# PIC32CX1025MTSH128 device description
Architecture: CORTEX-M4; Family: PIC32CXMT; Series: PIC32CXMTSH
Registers are 32-bit, read-write, no defined reset value unless marked. A register's access mark holds for its fields unless they carry their own. Offsets are from the block's base; [hi:lo] are bit positions; {n}, {i} and the like mark numbered series.

## CMCC — Cortex-M Cache Controller
Instances: CMCC0 0x46008000, CMCC1 0x4600C000
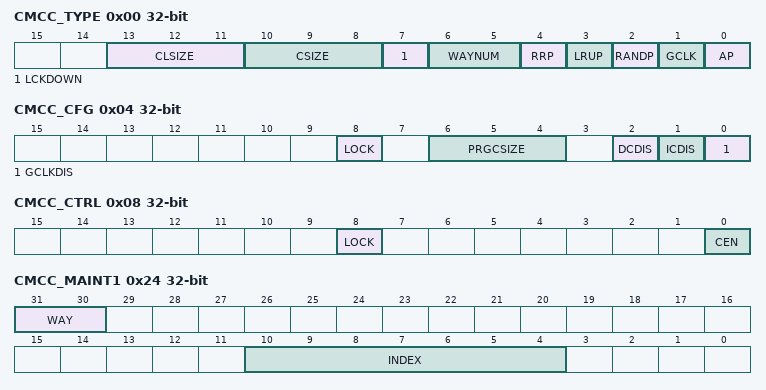
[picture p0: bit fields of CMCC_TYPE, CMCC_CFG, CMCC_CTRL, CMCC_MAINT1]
0x00 CMCC_TYPE ro — Cache Controller Type Register
  [13:11] CLSIZE — Cache LIne Size
    0=CLSIZE_1KB (Cache line size is 4 bytes); 1=CLSIZE_2KB (Cache line size is 8 bytes); 2=CLSIZE_4KB (Cache line size is 16 bytes); 3=CLSIZE_8KB (Cache line size is 32 bytes)
  [10:8] CSIZE — Data Cache Size
    0=CSIZE_1KB (Cache size is 1 Kbyte); 1=CSIZE_2KB (Cache size is 2 Kbytes); 2=CSIZE_4KB (Cache size is 4 Kbytes); 3=CSIZE_8KB (Cache size is 8 Kbytes); 4=CSIZE_16KB (Cache size is 16 Kbytes); 5=CSIZE_32KB (Cache size is 32 Kbytes); 6=CSIZE_64KB (Cache size is 64 Kbytes)
  [7] LCKDOWN — Lockdown Supported
  [6:5] WAYNUM — Number of Ways
    0=DMAPPED (Direct Mapped Cache); 1=ARCH2WAY (2-way set associative); 2=ARCH4WAY (4-way set associative); 3=ARCH8WAY (8-way set associative)
  [4] RRP — Random Selection Policy Supported
  [3] LRUP — Least Recently Used Policy Supported
  [2] RANDP — Random Selection Policy Supported
  [1] GCLK — Dynamic Clock Gating Supported
  [0] AP — Access Port Access Allowed
0x04 CMCC_CFG — Configuration Register
  [8] LOCK — Configuration Lock Until Next System Reset (Write-once)
  [6:4] PRGCSIZE — Programmable Cache Size
  [2] DCDIS — Data Caching Disable
  [1] ICDIS — Instruction Caching Disable
  [0] GCLKDIS — Disable Clock Gating
0x08 CMCC_CTRL wo — Control Register
  [8] LOCK — Control Lock Until Next System Reset (Write-once)
  [0] CEN — Cache Controller Enable
0x0C CMCC_SR ro — Status Register
  [0] CSTS — Cache Controller Status
0x20 CMCC_MAINT0 wo — Maintenance Register 0
  [0] INVALL — Cache Controller Invalidate All
0x24 CMCC_MAINT1 wo — Maintenance Register 1
  [31:30] WAY — Invalidate Way
    {v}=Way {v} is selection for index invalidation (v=0..3)
  [10:4] INDEX — Invalidate Index
0x28 CMCC_MCFG — Monitor Configuration Register
  [1:0] MODE — Cache Controller Monitor Counter Mode
    0=CYCLE_COUNT (Cycle counter); 1=IHIT_COUNT (Instruction hit counter, only relevant for unified cache and instruction cache architecture); 2=DHIT_COUNT (Data hit counter, only relevant for unified cache and data cache architecture)
0x2C CMCC_MEN — Monitor Enable Register
  [0] MENABLE — Cache Controller Monitor Enable
0x30 CMCC_MCTRL wo — Monitor Control Register
  [0] SWRST — Monitor
0x34 CMCC_MSR ro — Monitor Status Register
  [31:0] EVENT_CNT — Monitor Event Counter
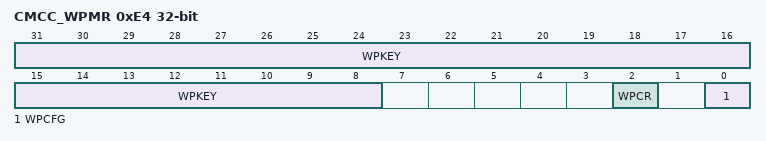
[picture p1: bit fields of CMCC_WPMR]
0xE4 CMCC_WPMR — Write Protection Mode Register
  [31:8] WPKEY — Write Protection Key
    0x434D43=PASSWD (Writing any other value in this field aborts the write operation of the WPCFG and WPCR bits. Always reads as 0.)
  [2] WPCR — Write Protection Control Enable
  [0] WPCFG — Write Protection Configuration Enable

## CPKCC — Classic Public Key Cryptography Controller
Instances: CPKCC 0x46000000
0x00 CPKCC_R — R Parameter Register
  [31:0] VALUE — CPKCC_R value
0x04 CPKCC_X — X Parameter Register
  [31:0] VALUE — CPKCC_X value
0x08 CPKCC_Y — Y Parameter Register
  [31:0] VALUE — CPKCC_Y value
0x0C CPKCC_Z — Z Parameter Register
  [31:0] VALUE — CPKCC_Z value
0x10 CPKCC_J — J Parameter Register
  [31:0] VALUE — CPKCC_J value
0x14 CPKCC_K — K Parameter Register
  [31:0] VALUE — CPKCC_K value
0x18 CPKCC_N — N Parameter Register
  [31:0] VALUE — CPKCC_N value
0x1C CPKCC_SMULA — SMULA Register
  [31:0] VALUE — CPKCC_SMULA value
0x20 CPKCC_SMULB — SMULB Register
  [31:0] VALUE — CPKCC_SMULB value
0x24 CPKCC_SMULRL — SMULRL Register
  [31:0] VALUE — CPKCC_SMULRL value
0x28 CPKCC_SMULRH — SMULRH Register
  [31:0] VALUE — CPKCC_SMULRH value
0x2C CPKCC_IDLE 8-bit — IDLE Register
  [7:0] VALUE — CPKCC_IDLE value
0x2D CPKCC_IDLECACHE 8-bit — IDLECACHE Register
  [7:0] VALUE — CPKCC_IDLECACHE value
0x30 CPKCC_CR_C — CR_C Register
  [31:0] VALUE — CPKCC_CR_C value
0x34 CPKCC_CR_S — CR_S Register
  [31:0] VALUE — CPKCC_CR_S value
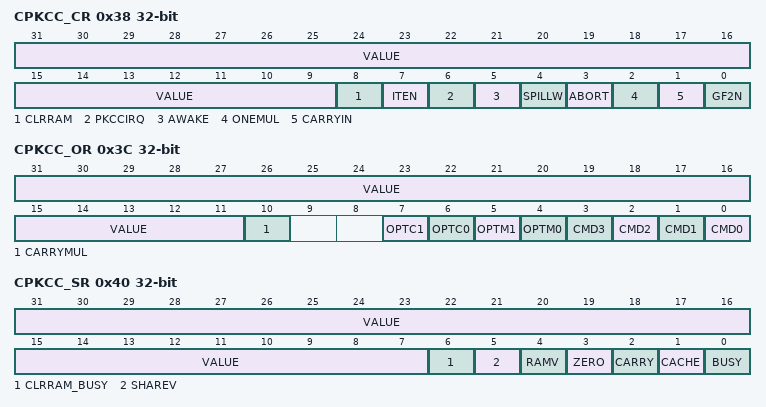
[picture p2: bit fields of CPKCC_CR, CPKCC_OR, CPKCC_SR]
0x38 CPKCC_CR — CR Register
  [31:9] VALUE — CPKCC_CR value
  [8] CLRRAM — CLRRAM value
  [7] ITEN — ITEN value
  [6] PKCCIRQ — CPKCC_IRQ value
  [5] AWAKE — AWAKE value
  [4] SPILLW — Spill Word register bit
  [3] ABORT — ABORT value
  [2] ONEMUL — ONEMUL value
  [1] CARRYIN — CARRYIN value
  [0] GF2N — GF(2n) mode
0x3C CPKCC_OR — Operation Register
  [31:11] VALUE — CPKCC_OR value
  [10] CARRYMUL — CARRYMUL value
  [7] OPTC1 — OPTC1 value
  [6] OPTC0 — OPTC0 value
  [5] OPTM1 — OPTM1 value
  [4] OPTM0 — OPTM0 value
  [n] CMD{n} (n=0..3) — CMD{n} value
0x40 CPKCC_SR — SR Register
  [31:7] VALUE — CPKCC_SR value
  [6] CLRRAM_BUSY — CLRRAM_BUSY value
  [5] SHAREV — SHAREV value
  [4] RAMV — RAM violation
  [3] ZERO — ZERO value
  [2] CARRY — CARRY value
  [1] CACHE — CACHE value
  [0] BUSY — BUSY value
0xEC CPKCC_ADDRSIZE — ADDRSIZE Register
  [31:0] VALUE — CPKCC_ADDRSIZE value
{0xF0+4i} CPKCC_IPNAME[{i}] (i=0..1) — IPNAME1 Register
  [31:0] VALUE — CPKCC_IPNAME1 value
0xF8 CPKCC_FEATURES — FEATURES Register
  [31:0] VALUE — CPKCC_FEATURES value

## Notices in the file
Copyright %copyright_year% Microchip Technology Inc.
SPDX-License-Identifier: Apache-2.0
Licensed under the Apache License, Version 2.0 (the "License");
you may not use this file except in compliance with the License.
You may obtain a copy of the License at
http://www.apache.org/licenses/LICENSE-2.0
Unless required by applicable law or agreed to in writing, software
distributed under the License is distributed on an "AS IS" BASIS,
WITHOUT WARRANTIES OR CONDITIONS OF ANY KIND, either express or implied.
See the License for the specific language governing permissions and
limitations under the License.
